AUTOSAR XML (schema 00044)
package /ComponentTypes
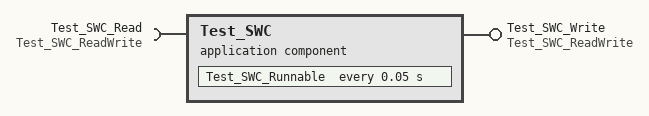
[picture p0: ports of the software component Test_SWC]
  application sw component type Test_SWC
    require port Test_SWC_Read: nonqueued-receiver-com-spec{data-element=Element, init-value=0}, required-interface=Test_SWC_ReadWrite
    provide port Test_SWC_Write: nonqueued-sender-com-spec{data-element=Element, init-value=0}, provided-interface=Test_SWC_ReadWrite
    behavior Test_SWC_InternalBehavior
      timing event TMT_Test_SWC_Runnable: start-on-event=Test_SWC_Runnable, period=0.05
      runnable Test_SWC_Runnable: minimum-start-interval=0.05
        data-receive-point-by-arguments:
          access REC_Test_SWC_Read_Element: accessed-variable=Test_SWC_Read.Element
        data-send-points:
          access SEND_Test_SWC_ReadWrite_Element: accessed-variable=Test_SWC_Write.Element
  swc implementation Test_SWC_Implementation: behavior=Test_SWC_InternalBehavior
